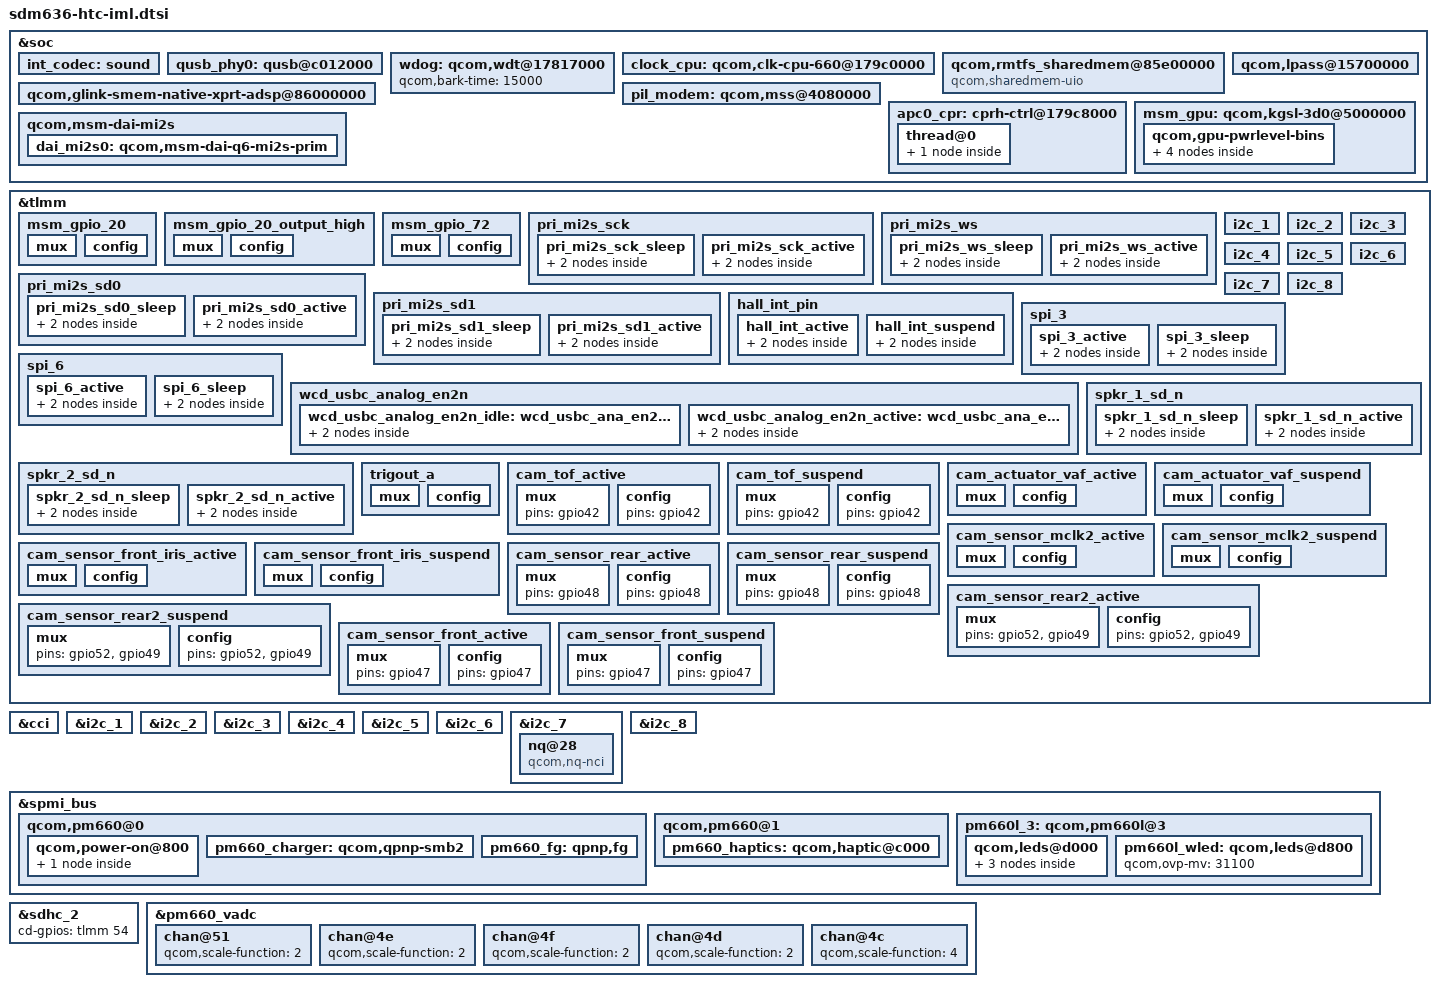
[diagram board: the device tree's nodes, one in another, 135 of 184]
/* Copyright (c) 2017, The Linux Foundation. All rights reserved.
*
* This program is free software; you can redistribute it and/or modify
* it under the terms of the GNU General Public License version 2 and
* only version 2 as published by the Free Software Foundation.
*
* This program is distributed in the hope that it will be useful,
* but WITHOUT ANY WARRANTY; without even the implied warranty of
* MERCHANTABILITY or FITNESS FOR A PARTICULAR PURPOSE.  See the
* GNU General Public License for more details.
*/

#include "sdm630-htc-common.dtsi"
#include "dsi-panel-htc-iml.dtsi"
#include "sdm630-htc-iml-camera-sensor.dtsi"
#include "sdm636-htc-iml-touch.dtsi"
#include "charger-htc-iml.dtsi"
#include "sdm636-htc-iml-codec.dtsi"
#include "sdm630-htc-nfc.dtsi"
#include "sdm630-htc-sensors.dtsi"

&soc {
	int_codec: sound {
		qcom,msm-micbias1-ext-cap;
		qcom,msm-hs-micbias-type = "external";
		qcom,audio-routing =
		"RX_BIAS", "INT_MCLK0",
		"SPK_RX_BIAS", "INT_MCLK0",
		"INT_LDO_H", "INT_MCLK0",
		"RX_I2S_CLK", "INT_MCLK0",
		"TX_I2S_CLK", "INT_MCLK0",
		"MIC BIAS External", "Handset Mic",
		"MIC BIAS External2", "Headset Mic",
		"MIC BIAS External", "Secondary Mic",
		"AMIC1", "MIC BIAS External",
		"AMIC2", "MIC BIAS External2",
		"AMIC3", "MIC BIAS External",
		"DMIC1", "MIC BIAS External",
		"MIC BIAS External", "Digital Mic1",
		"DMIC2", "MIC BIAS External",
		"MIC BIAS External", "Digital Mic2",
		"DMIC3", "MIC BIAS External",
		"MIC BIAS External", "Digital Mic3",
		"DMIC4", "MIC BIAS External",
		"MIC BIAS External", "Digital Mic4",
		"SpkrLeft IN", "SPK1 OUT",
		"SpkrRight IN", "SPK2 OUT",
		"PDM_IN_RX1", "PDM_OUT_RX1",
		"PDM_IN_RX2", "PDM_OUT_RX2",
		"PDM_IN_RX3", "PDM_OUT_RX3",
		"ADC1_IN", "ADC1_OUT",
		"ADC2_IN", "ADC2_OUT",
		"ADC3_IN", "ADC3_OUT";
		
		qcom,wsa-max-devs = <2>;
		qcom,wsa-aux-dev-prefix = "SpkrLeft", "SpkrRight",
		"SpkrLeft", "SpkrRight";
	};
	
	qusb_phy0: qusb@c012000 {
		qcom,tune2-efuse-num-bits = <0x04>;
		qcom,qusb-phy-init-seq = <0xf8 0x80
		0xb3 0x84
		0x83 0x88
		0xc0 0x8c
		0x30 0x08
		0x79 0x0c
		0x21 0x10
		0x14 0x9c
		0x9f 0x1c
		0x00 0x18>;
	};

	wdog: qcom,wdt@17817000 {
		qcom,bark-time = <15000>;
	};

	clock_cpu: qcom,clk-cpu-660@179c0000 {
		reg = <0x179c0000 0x4000>, <0x17916000 0x1000>,
		      <0x17816000 0x1000>, <0x179d1000 0x1000>,
		      <0x00784130 0x8>, <0x00784130 0x8>, 
			  <0x17914800 0x800>;
		reg-names = "osm", "pwrcl_pll", "perfcl_pll",
				"apcs_common", "pwrcl_efuse",
				"perfcl_efuse", "pwrcl_acd";
		qcom,acdtd-val = <0xa111 0xa111>;
		qcom,acdcr-val = <0x2c5ffd 0x2c5ffd>;
		qcom,acdsscr-val = <0x901 0x901>;
		qcom,acdextint0-val = <0x2cf9ae8 0x2cf9ae8>;
		qcom,acdextint1-val = <0x2cf9afe 0x2cf9afe>;
		qcom,acdautoxfer-val = <0x15 0x15>;
		qcom,pc-override-index = <0x00 0x00>;
	};

	/delete-node/ qcom,rmtfs_sharedmem@0;

	qcom,rmtfs_sharedmem@85e00000 {
		compatible = "qcom,sharedmem-uio";
		reg = <0x85e00000 0x200000>;
		reg-names = "rmtfs";
		qcom,client-id = <0x00000001>;
	};

	qcom,glink-smem-native-xprt-adsp@86000000 {
		/delete-property/ cpu-affinity;
	};

	qcom,lpass@15700000 {
		/delete-property/ reg-names;
	};

	pil_modem: qcom,mss@4080000 {
		/delete-property/ qcom,complete-ramdump;
	};

	/* This is probably not needed now that we are building for a version
	* after original kernel and this change was introduced later.
	* Also our device is eMMC.
	ufs1: ufshc@1da4000 {
		/delete-property/ pinctrl-names;
		/delete-property/ pinctrl-0;
		/delete-property/ pinctrl-1;
	};
	*/
	apc0_cpr: cprh-ctrl@179c8000 {
		thread@0 {
			apc0_pwrcl_vreg: regulator {
				qcom,cpr-closed-loop-voltage-fuse-adjustment =
					<(-32000) (-30000) (-29000) (-38000)
					(-36000)>;
			};
		};
	};

	msm_gpu: qcom,kgsl-3d0@5000000 {
		qcom,gpu-pwrlevel-bins {
			qcom,gpu-pwrlevels-3 {
				/* SVS_L1 */
				qcom,gpu-pwrlevel@2 {
					qcom,bus-freq = <10>;
					qcom,bus-min = <9>;
					qcom,bus-max = <11>;
				};

				/* SVS */
				qcom,gpu-pwrlevel@3 {
					qcom,bus-freq = <9>;
					qcom,bus-min = <9>;
					qcom,bus-max = <11>;
				};

				/* Low SVS */
				qcom,gpu-pwrlevel@4 {
					qcom,bus-freq = <4>;
					qcom,bus-max = <8>;
				};
			};

			/delete-node/ qcom,gpu-pwrlevels-6;
		};
	};

	qcom,msm-dai-mi2s {
		dai_mi2s0: qcom,msm-dai-q6-mi2s-prim {
			qcom,msm-mi2s-rx-lines = <1>;
			qcom,msm-mi2s-tx-lines = <2>;
		};
	};
};

&tlmm {
	/* This is probably not needed now that we are building for a version
	* after original kernel and this change was introduced later.
	* Also our device is eMMC.
	/delete-node/ ufs_dev_reset_assert;
	*/	

	msm_gpio_20: msm_gpio_20 {
		mux{
			pins="gpio20";
			function= "gpio";
		};
		config {
			pins= "gpio20";
			drive-strength = <2>;
			bias-disable;
			output-low;
		
		};
	};

	msm_gpio_20_output_high: msm_gpio_20_output_high {
		mux {
			pins = "gpio20";
			function = "gpio";

		};
		config{
			pins = "gpio20";
			drive-strength = <2>;
			bias-disable;
			output-high;
		};
	
	};

	msm_gpio_72: msm_gpio_72{
		mux{
			pins = "gpio72";
			function = "gpio";
		};
		config{
			pins = "gpio72";
			drive-strength=<2>;
			bias-pull-down;
		};
	};

	pri_mi2s_sck {
		pri_mi2s_sck_sleep: pri_mi2s_sck_sleep {
			mux {
				pins = "gpio12";
				function = "gpio";
			};

			config {
				pins = "gpio12";
				drive-strength = <2>;   /* 2 mA */
				bias-pull-down;         /* PULL DOWN */
				input-enable;
			};
		};

		pri_mi2s_sck_active: pri_mi2s_sck_active {
			mux {
				pins = "gpio12";
				function = "pri_mi2s";
			};

			config {
				pins = "gpio12";
				drive-strength = <8>;   /* 8 mA */
				bias-disable;           /* NO PULL */
				output-high;
			};
		};
	};

	pri_mi2s_ws {
		pri_mi2s_ws_sleep: pri_mi2s_ws_sleep {
			mux {
				pins = "gpio13";
				function = "gpio";
			};

			config {
				pins = "gpio13";
				drive-strength = <2>;   /* 2 mA */
				bias-pull-down;         /* PULL DOWN */
				input-enable;
			};
		};

		pri_mi2s_ws_active: pri_mi2s_ws_active {
			mux {
				pins = "gpio13";
				function = "pri_mi2s_ws";
			};

			config {
				pins = "gpio13";
				drive-strength = <8>;   /* 8 mA */
				bias-disable;           /* NO PULL */
				output-high;
			};
		};
	};

	pri_mi2s_sd0 {
		pri_mi2s_sd0_sleep: pri_mi2s_sd0_sleep {
			mux {
				pins = "gpio14";
				function = "gpio";
			};

			config {
				pins = "gpio14";
				drive-strength = <2>;   /* 2 mA */
				bias-pull-down;         /* PULL DOWN */
				input-enable;
			};
		};

		pri_mi2s_sd0_active: pri_mi2s_sd0_active {
			mux {
				pins = "gpio14";
				function = "pri_mi2s";
			};

			config {
				pins = "gpio14";
				drive-strength = <8>;   /* 8 mA */
				bias-disable;           /* NO PULL */
			};
		};
	};

	pri_mi2s_sd1 {
		pri_mi2s_sd1_sleep: pri_mi2s_sd1_sleep {
			mux {
				pins = "gpio15";
				function = "gpio";
			};

			config {
				pins = "gpio15";
				drive-strength = <2>;   /* 2 mA */
				bias-pull-down;         /* PULL DOWN */
				input-enable;
			};
		};

		pri_mi2s_sd1_active: pri_mi2s_sd1_active {
			mux {
				pins = "gpio15";
				function = "pri_mi2s";
			};

			config {
				pins = "gpio15";
				drive-strength = <8>;   /* 8 mA */
				bias-disable;           /* NO PULL */
			};
		};
	};

	hall_int_pin: hall_int_pin {
		hall_int_active: hall_int_active {
			mux {
				pins = "gpio75";
				function = "gpio";
			};

			config {
				pins = "gpio75";
				drive-strength = <0x6>;
				bias-pull-up;
			};
		};

		hall_int_suspend: hall_int_suspend {
			mux {
				pins = "gpio75";
				function = "gpio";
			};

			config {
				pins = "gpio75";
				drive-strength = <0x6>;
				bias-pull-up;
			};
		};
	};

	i2c_1 {
		/delete-node/ i2c_1_bitbang;
	};

	i2c_2 {
		/delete-node/ i2c_2_bitbang;
	};

	i2c_3 {
		/delete-node/ i2c_3_bitbang;
	};

	i2c_4 {
		/delete-node/ i2c_4_bitbang;
	};

	i2c_5 {
		/delete-node/ i2c_5_bitbang;
	};

	i2c_6 {
		/delete-node/ i2c_6_bitbang;
	};

	i2c_7 {
		/delete-node/ i2c_7_bitbang;
	};

	i2c_8 {
		/delete-node/ i2c_8_bitbang;
	};

	spi_3 {
		spi_3_active: spi_3_active {
			mux {
				/delete-property/ pins;/* PROPERTY UNDEFINED IN STOCK. TODO: CONFIRM IF IT ID NEEDED */
			};

			config {
				/delete-property/ pins;/* PROPERTY UNDEFINED IN STOCK. TODO: CONFIRM IF IT ID NEEDED */
			};
		};

		spi_3_sleep: spi_3_sleep {
			mux {
				/delete-property/ pins;/* PROPERTY UNDEFINED IN STOCK. TODO: CONFIRM IF IT ID NEEDED */
			};

			config {
				/delete-property/ pins;/* PROPERTY UNDEFINED IN STOCK. TODO: CONFIRM IF IT ID NEEDED */
			};
		};
	};

	spi_6 {
		spi_6_active: spi_6_active {
			mux {
				pins = "gpio22", "gpio23";/* TODO: CONFIRM IF IT IS CORRECT */
			};

			config {
				pins = "gpio22", "gpio23";/* TODO: CONFIRM IF IT IS CORRECT */
			};
		};

		spi_6_sleep: spi_6_sleep {
			mux {
				pins = "gpio22", "gpio23";/* TODO: CONFIRM IF IT IS CORRECT */
			};

			config {
				pins = "gpio22", "gpio23";/* TODO: CONFIRM IF IT IS CORRECT */
			};
		};
	};

	wcd_usbc_analog_en2n {
		wcd_usbc_analog_en2n_idle: wcd_usbc_ana_en2n_idle {
			mux {
				/delete-property/ pins;/* PROPERTY UNDEFINED IN STOCK. TODO: CONFIRM IF IT ID NEEDED */
			};

			config {
				/delete-property/ pins;/* PROPERTY UNDEFINED IN STOCK. TODO: CONFIRM IF IT ID NEEDED */
			};
		};

		wcd_usbc_analog_en2n_active: wcd_usbc_ana_en2n_active {
			mux {
				/delete-property/ pins;/* PROPERTY UNDEFINED IN STOCK. TODO: CONFIRM IF IT ID NEEDED */
			};

			config {
				/delete-property/ pins;/* PROPERTY UNDEFINED IN STOCK. TODO: CONFIRM IF IT ID NEEDED */
			};
		};
	};

	spkr_1_sd_n {
		spkr_1_sd_n_sleep: spkr_1_sd_n_sleep {
			mux {
				/delete-property/ pins;/* PROPERTY UNDEFINED IN STOCK. TODO: CONFIRM IF IT ID NEEDED */
			};

			config {
				/delete-property/ pins;/* PROPERTY UNDEFINED IN STOCK. TODO: CONFIRM IF IT ID NEEDED */
			};
		};

		spkr_1_sd_n_active: spkr_1_sd_n_active {
			mux {
				/delete-property/ pins;/* PROPERTY UNDEFINED IN STOCK. TODO: CONFIRM IF IT ID NEEDED */
			};

			config {
				/delete-property/ pins;/* PROPERTY UNDEFINED IN STOCK. TODO: CONFIRM IF IT ID NEEDED */
			};
		};
	};

	spkr_2_sd_n {
		spkr_2_sd_n_sleep: spkr_2_sd_n_sleep {
			mux {
				/delete-property/ pins;/* PROPERTY UNDEFINED IN STOCK. TODO: CONFIRM IF IT ID NEEDED */
			};

			config {
				/delete-property/ pins;/* PROPERTY UNDEFINED IN STOCK. TODO: CONFIRM IF IT ID NEEDED */
			};
		};

		spkr_2_sd_n_active: spkr_2_sd_n_active {
			mux {
				/delete-property/ pins;/* PROPERTY UNDEFINED IN STOCK. TODO: CONFIRM IF IT ID NEEDED */
			};

			config {
				/delete-property/ pins;/* PROPERTY UNDEFINED IN STOCK. TODO: CONFIRM IF IT ID NEEDED */
			};
		};
	};

	/* DIFF: MALFORMED IN STOCK DTS. DEFINED FOR FUTURE OVERRIDES. IF USING THIS NODE, THEN REMOVE DELETE NODE DIRECTIVE BELOW */
	trigout_a: trigout_a {
		mux {
			/delete-property/ pins; /* pins = "gpio49"; PROPERTY UNDEFINED IN STOCK. TODO: CONFIRM IF IT ID NEEDED */
		};

		config {
			/delete-property/ pins; /* pins = "gpio49"; PROPERTY UNDEFINED IN STOCK. TODO: CONFIRM IF IT ID NEEDED */
		};
	};

	cam_tof_active: cam_tof_active {
		/* LASER */
		mux {
			pins = "gpio42";
		};

		config {
			pins = "gpio42";
		};
	};

	cam_tof_suspend: cam_tof_suspend {
		/* LASER */
		mux {
			pins = "gpio42";
		};

		config {
			pins = "gpio42";
		};
	};

	cam_actuator_vaf_active: cam_actuator_vaf_active {
		/* ACTUATOR POWER */
		mux {
			/delete-property/ pins; /* pins = "gpio50"; PROPERTY UNDEFINED IN STOCK. TODO: CONFIRM IF IT ID NEEDED */
		};

		config {
			/delete-property/ pins; /* pins = "gpio50"; PROPERTY UNDEFINED IN STOCK. TODO: CONFIRM IF IT ID NEEDED */
		};
	};

	cam_actuator_vaf_suspend: cam_actuator_vaf_suspend {
		/* ACTUATOR POWER */
		mux {
			/delete-property/ pins; /* pins = "gpio50"; PROPERTY UNDEFINED IN STOCK. TODO: CONFIRM IF IT ID NEEDED */
		};

		config {
			/delete-property/ pins; /* pins = "gpio50"; PROPERTY UNDEFINED IN STOCK. TODO: CONFIRM IF IT ID NEEDED */
		};
	};

	cam_sensor_mclk2_active: cam_sensor_mclk2_active {
		/* MCLK1 */
		mux {
			/* CLK */
			/delete-property/ pins; /* pins = "gpio34"; PROPERTY UNDEFINED IN STOCK. TODO: CONFIRM IF IT ID NEEDED */
		};

		config {
			/delete-property/ pins; /* pins = "gpio34"; PROPERTY UNDEFINED IN STOCK. TODO: CONFIRM IF IT ID NEEDED */
		};
	};

	cam_sensor_mclk2_suspend: cam_sensor_mclk2_suspend {
		/* MCLK1 */
		mux {
			/* CLK */
			/delete-property/ pins; /* pins = "gpio34"; PROPERTY UNDEFINED IN STOCK. TODO: CONFIRM IF IT ID NEEDED */
		};

		config {
			/delete-property/ pins; /* pins = "gpio34"; PROPERTY UNDEFINED IN STOCK. TODO: CONFIRM IF IT ID NEEDED */
		};
	};

	cam_sensor_front_iris_active: cam_sensor_front_iris_active {
		/* RESET */
		mux {
			/delete-property/ pins; /* pins = "gpio52"; PROPERTY UNDEFINED IN STOCK. TODO: CONFIRM IF IT ID NEEDED */
		};

		config {
			/delete-property/ pins; /* pins = "gpio52"; PROPERTY UNDEFINED IN STOCK. TODO: CONFIRM IF IT ID NEEDED */
		};
	};

	cam_sensor_front_iris_suspend: cam_sensor_front_iris_suspend {
		/* RESET */
		mux {
			/delete-property/ pins; /* pins = "gpio52"; PROPERTY UNDEFINED IN STOCK. TODO: CONFIRM IF IT ID NEEDED */
		};

		config {
			/delete-property/ pins; /* pins = "gpio52"; PROPERTY UNDEFINED IN STOCK. TODO: CONFIRM IF IT ID NEEDED */
		};
	};

	cam_sensor_rear_active: cam_sensor_rear_active {
		mux {
			pins = "gpio48";
		};

		config {
			pins = "gpio48";
		};
	};

	cam_sensor_rear_suspend: cam_sensor_rear_suspend {
		mux {
			pins = "gpio48";
		};

		config {
			pins = "gpio48";
		};
	};

	cam_sensor_rear2_active: cam_sensor_rear2_active {
		/* RESET, STANDBY */
		mux {
			pins = "gpio52", "gpio49";
		};

		config {
			pins = "gpio52", "gpio49";
		};
	};

	cam_sensor_rear2_suspend: cam_sensor_rear2_suspend {
		/* RESET, STANDBY */
		mux {
			pins = "gpio52", "gpio49";
		};
		config {
			pins = "gpio52", "gpio49";
		};
	};

	cam_sensor_front_active: cam_sensor_front_active {
		mux {
			pins = "gpio47";
		};

		config {
			pins = "gpio47";
		};
	};

	cam_sensor_front_suspend: cam_sensor_front_suspend {
		mux {
			pins = "gpio47";
		};

		config {
			pins = "gpio47";
		};
	};
};

&cci {
	/delete-node/ qcom,ois@0;
	/delete-node/ qcom,tof@29;
};

&i2c_1 {
	/delete-property/ pinctrl-2;
	pinctrl-names = "i2c_active", "i2c_sleep";
};

&i2c_2 {
	/delete-property/ pinctrl-2;
	pinctrl-names = "i2c_active", "i2c_sleep";
};

&i2c_3 {
	/delete-property/ pinctrl-2;
	pinctrl-names = "i2c_active", "i2c_sleep";
};

&i2c_4 {
	/delete-property/ pinctrl-2;
	pinctrl-names = "i2c_active", "i2c_sleep";
};

&i2c_5 {
	/delete-property/ pinctrl-2;
	pinctrl-names = "i2c_active", "i2c_sleep";
};

&i2c_6 {
	/delete-property/ pinctrl-2;
	pinctrl-names = "i2c_active", "i2c_sleep";
};

&i2c_7 {
	/delete-property/ pinctrl-2;
	pinctrl-names = "i2c_active", "i2c_sleep";
};

&i2c_8 {
	/delete-property/ pinctrl-2;
	pinctrl-names = "i2c_active", "i2c_sleep";
};

&i2c_6 {
	/delete-node/ nq@28;
};

&i2c_7 {
	status = "okay";
	nq@28 {
		compatible = "qcom,nq-nci";
		reg = <0x28>;
		qcom,nq-irq = <&tlmm 28 0x00>;
		qcom,nq-ven = <&tlmm 29 0x00>;
		qcom,nq-firm = <&tlmm 30 0x00>;
		qcom,nq-clkreq = <&pm660_gpios 4 0x00>;
		qcom,nq-esepwr = <&tlmm 31 0x00>;
		interrupt-parent = <&tlmm>;
		qcom,clk-src = "BBCLK3";
		interrupts = <28 0>;
		interrupt-names = "nfc_irq";
		pinctrl-names = "nfc_active", "nfc_suspend";
		pinctrl-0 = <&nfc_int_active &nfc_enable_active>;
		pinctrl-1 = <&nfc_int_suspend &nfc_enable_suspend>;
		clocks = <&clock_rpmcc RPM_LN_BB_CLK3_PIN>;
		clock-names = "ref_clk";
	};
};

/* Remove useless node
&hostless {
	audio_test_mod {
		compatible = "qcom,audio-test-mod";
	};
};
*/

&spmi_bus {
	qcom,pm660@0 {
		qcom,power-on@800 {
			qcom,pon_1 {
				qcom,support-reset = <1>;
				qcom,s1-timer = <4480>;
				qcom,s2-timer = <2000>;
				qcom,s2-type = <7>;
			};
		};

		pm660_charger: qcom,qpnp-smb2 {
			qcom,usb-icl-ua = <2150000>;
			qcom,dc-icl-ua = <2150000>;
			qcom,fcc-max-ua = <2150000>;
			qcom,fv-max-uv = <4400000>;
			qcom,sw-jeita-enable;
			qcom,thermal-mitigation
					= <2000000 1500000 1000000 800000
						500000 200000>;
		};

		pm660_fg: qpnp,fg {
			qcom,fg-jeita-thresholds = <0x03 0x0a 0x2d 0x32>;
			qcom,fg-chg-term-current = <150>;
			qcom,fg-sys-term-current = <0xfffffed4>;
			qcom,fg-jeita-hyst-temp = <3>;
			qcom,fg-recharge-voltage = <4350>;
		};
	};

	qcom,pm660@1 {
		pm660_haptics: qcom,haptic@c000 {
			qcom,actuator-type = "erm";
			qcom,vmax-mv = <3000>;
			qcom,brake-pattern = <0x00>;
		};
	};

	pm660l_3: qcom,pm660l@3 {
		qcom,leds@d000 {
			red_led: qcom,rgb_0 {
				qcom,idx-len = <100>;
				qcom,duty-pcts = [64 00 00 00 00 00 00 00 00 00 00];
			};

			green_led: qcom,rgb_1 {
				qcom,start-idx = <0>;
				qcom,idx-len = <100>;
				qcom,duty-pcts = [64 00 00 00 00 00 00 00 00 00 00];
				qcom,use-blink;
			};
			
			blue_led: qcom,rgb_2 {
				qcom,idx-len = <100>;
				qcom,duty-pcts = <64 00 00 00 00 00 00 00 00 00 00>;
				qcom,use-blink;
			};

		};
		
		pm660l_wled: qcom,leds@d800 {
			qcom,ovp-mv = <31100>;
		};
	};
};

&sdhc_2 {
	cd-gpios = <&tlmm 54 0x0>;
};

&pm660_vadc {
	chan@51 { /* quiet_therm */
		qcom,scale-function = <2>;
	};
	
	chan@4e { /* emmc_therm */
		qcom,scale-function = <2>;
	};
	
	chan@4f { /* pa_therm0 */
		qcom,scale-function = <2>;
	};
	
	chan@4d { /* msm_therm */
		qcom,scale-function = <2>;
	};
	
	chan@4c { /* xo_therm */
		qcom,scale-function = <4>;
	};
};

